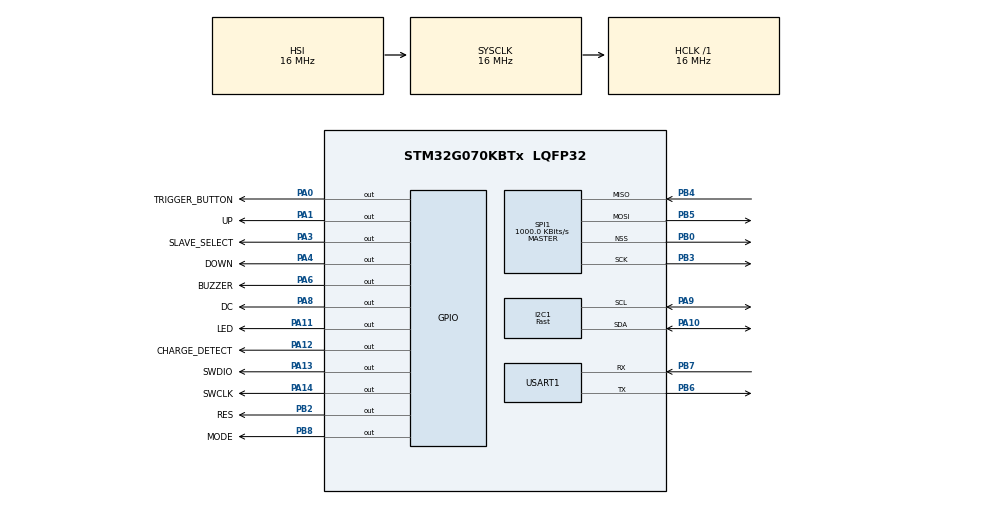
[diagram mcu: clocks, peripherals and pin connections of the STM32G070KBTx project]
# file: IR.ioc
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I2C1.I2C_Speed_Mode=I2C_Fast
I2C1.Timing=0x0010061A
Mcu.Family=STM32G0
Mcu.Name=STM32G070KBTx
Mcu.Package=LQFP32
NRST.GPIO_Label=NRST
NRST.Signal=GPIO_Output
PA0.GPIO_Label=TRIGGER_BUTTON
PA0.Signal=GPIO_Output
PA1.GPIO_Label=UP
PA1.Signal=GPIO_Output
PA10.Mode=I2C
PA10.Signal=I2C1_SDA
PA11\ [PA9].GPIO_Label=LED
PA11\ [PA9].Signal=GPIO_Output
PA12\ [PA10].GPIO_Label=CHARGE_DETECT
PA12\ [PA10].Signal=GPIO_Output
PA13.GPIO_Label=SWDIO
PA13.Signal=GPIO_Output
PA14-BOOT0.GPIO_Label=SWCLK
PA14-BOOT0.Signal=GPIO_Output
PA3.GPIO_Label=SLAVE_SELECT
PA3.PinState=GPIO_PIN_SET
PA3.Signal=GPIO_Output
PA4.GPIO_Label=DOWN
PA4.Signal=GPIO_Output
PA6.GPIO_Label=BUZZER
PA6.Signal=GPIO_Output
PA8.GPIO_Label=DC
PA8.Signal=GPIO_Output
PA9.Mode=I2C
PA9.Signal=I2C1_SCL
PB0.Mode=NSS_Signal_Hard_Output
PB0.Signal=SPI1_NSS
PB2.GPIO_Label=RES
PB2.Signal=GPIO_Output
PB3.Mode=Full_Duplex_Master
PB3.Signal=SPI1_SCK
PB4.Mode=Full_Duplex_Master
PB4.Signal=SPI1_MISO
PB5.Mode=Full_Duplex_Master
PB5.Signal=SPI1_MOSI
PB6.Mode=Asynchronous
PB6.Signal=USART1_TX
PB7.Mode=Asynchronous
PB7.Signal=USART1_RX
PB8.GPIO_Label=MODE
PB8.Signal=GPIO_Output
ProjectManager.HeapSize=0x200
ProjectManager.StackSize=0x400
ProjectManager.TargetToolchain=MDK-ARM V5.27
RCC.AHBFreq_Value=16000000
RCC.CortexFreq_Value=16000000
RCC.EXTERNAL_CLOCK_VALUE=48000
RCC.HCLKFreq_Value=16000000
RCC.HSE_VALUE=8000000
RCC.HSI_VALUE=16000000
RCC.LSE_VALUE=32768
RCC.SYSCLKFreq_VALUE=16000000
RCC.VCOOutputFreq_Value=128000000
SPI1.BaudRatePrescaler=SPI_BAUDRATEPRESCALER_16
SPI1.CalculateBaudRate=1000.0 KBits/s
SPI1.Direction=SPI_DIRECTION_2LINES
SPI1.Mode=SPI_MODE_MASTER
SPI1.VirtualNSS=VM_NSSHARD
SPI1.VirtualType=VM_MASTER
USART1.VirtualMode-Asynchronous=VM_ASYNC
USART1.WordLength=WORDLENGTH_7B
VP_SYS_VS_DBSignals.Mode=DisableDeadBatterySignals
board=custom

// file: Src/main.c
/* USER CODE BEGIN Header */
/**
  ******************************************************************************
  * @file           : main.c
  * @brief          : Main program body
  ******************************************************************************
  * @attention
  *
  * <h2><center>&copy; Copyright (c) 2020 STMicroelectronics.
  * All rights reserved.</center></h2>
  *
  * This software component is licensed by ST under BSD 3-Clause license,
  * the "License"; You may not use this file except in compliance with the
  * License. You may obtain a copy of the License at:
  *                        opensource.org/licenses/BSD-3-Clause
  *
  ******************************************************************************
  */
/* USER CODE END Header */

#include "main.h"

/* USER CODE BEGIN Includes */
//#include "st7735.h"

/* USER CODE END Includes */

I2C_HandleTypeDef hi2c1;

SPI_HandleTypeDef hspi1;

UART_HandleTypeDef huart1;

void SystemClock_Config(void);
static void MX_GPIO_Init(void);
static void MX_I2C1_Init(void);
static void MX_SPI1_Init(void);
static void MX_USART1_UART_Init(void);

int main(void)
{

  /* MCU Configuration--------------------------------------------------------*/

  /* Reset of all peripherals, Initializes the Flash interface and the Systick. */
  HAL_Init();

  /* Configure the system clock */
  SystemClock_Config();

  /* Initialize all configured peripherals */
  MX_GPIO_Init();
  MX_I2C1_Init();
  MX_SPI1_Init();
  MX_USART1_UART_Init();

  /* Infinite loop */
  while (1)
  {

  }
}

void SystemClock_Config(void)
{
  RCC_OscInitTypeDef RCC_OscInitStruct = {0};
  RCC_ClkInitTypeDef RCC_ClkInitStruct = {0};
  RCC_PeriphCLKInitTypeDef PeriphClkInit = {0};

  /** Configure the main internal regulator output voltage
  */
  HAL_PWREx_ControlVoltageScaling(PWR_REGULATOR_VOLTAGE_SCALE1);
  /** Initializes the CPU, AHB and APB busses clocks
  */
  RCC_OscInitStruct.OscillatorType = RCC_OSCILLATORTYPE_HSI;
  RCC_OscInitStruct.HSIState = RCC_HSI_ON;
  RCC_OscInitStruct.HSIDiv = RCC_HSI_DIV1;
  RCC_OscInitStruct.HSICalibrationValue = RCC_HSICALIBRATION_DEFAULT;
  RCC_OscInitStruct.PLL.PLLState = RCC_PLL_NONE;
  if (HAL_RCC_OscConfig(&RCC_OscInitStruct) != HAL_OK)
  {
    Error_Handler();
  }
  /** Initializes the CPU, AHB and APB busses clocks
  */
  RCC_ClkInitStruct.ClockType = RCC_CLOCKTYPE_HCLK|RCC_CLOCKTYPE_SYSCLK
                              |RCC_CLOCKTYPE_PCLK1;
  RCC_ClkInitStruct.SYSCLKSource = RCC_SYSCLKSOURCE_HSI;
  RCC_ClkInitStruct.AHBCLKDivider = RCC_SYSCLK_DIV1;
  RCC_ClkInitStruct.APB1CLKDivider = RCC_HCLK_DIV1;

  if (HAL_RCC_ClockConfig(&RCC_ClkInitStruct, FLASH_LATENCY_0) != HAL_OK)
  {
    Error_Handler();
  }
  /** Initializes the peripherals clocks
  */
  PeriphClkInit.PeriphClockSelection = RCC_PERIPHCLK_USART1|RCC_PERIPHCLK_I2C1;
  PeriphClkInit.Usart1ClockSelection = RCC_USART1CLKSOURCE_PCLK1;
  PeriphClkInit.I2c1ClockSelection = RCC_I2C1CLKSOURCE_PCLK1;
  if (HAL_RCCEx_PeriphCLKConfig(&PeriphClkInit) != HAL_OK)
  {
    Error_Handler();
  }
}

static void MX_I2C1_Init(void)
{

  hi2c1.Instance = I2C1;
  hi2c1.Init.Timing = 0x0010061A;
  hi2c1.Init.OwnAddress1 = 0;
  hi2c1.Init.AddressingMode = I2C_ADDRESSINGMODE_7BIT;
  hi2c1.Init.DualAddressMode = I2C_DUALADDRESS_DISABLE;
  hi2c1.Init.OwnAddress2 = 0;
  hi2c1.Init.OwnAddress2Masks = I2C_OA2_NOMASK;
  hi2c1.Init.GeneralCallMode = I2C_GENERALCALL_DISABLE;
  hi2c1.Init.NoStretchMode = I2C_NOSTRETCH_DISABLE;
  if (HAL_I2C_Init(&hi2c1) != HAL_OK)
  {
    Error_Handler();
  }
  /** Configure Analogue filter
  */
  if (HAL_I2CEx_ConfigAnalogFilter(&hi2c1, I2C_ANALOGFILTER_ENABLE) != HAL_OK)
  {
    Error_Handler();
  }
  /** Configure Digital filter
  */
  if (HAL_I2CEx_ConfigDigitalFilter(&hi2c1, 0) != HAL_OK)
  {
    Error_Handler();
  }

}

static void MX_SPI1_Init(void)
{

  /* SPI1 parameter configuration*/
  hspi1.Instance = SPI1;
  hspi1.Init.Mode = SPI_MODE_MASTER;
  hspi1.Init.Direction = SPI_DIRECTION_2LINES;
  hspi1.Init.DataSize = SPI_DATASIZE_4BIT;
  hspi1.Init.CLKPolarity = SPI_POLARITY_LOW;
  hspi1.Init.CLKPhase = SPI_PHASE_1EDGE;
  hspi1.Init.NSS = SPI_NSS_HARD_OUTPUT;
  hspi1.Init.BaudRatePrescaler = SPI_BAUDRATEPRESCALER_16;
  hspi1.Init.FirstBit = SPI_FIRSTBIT_MSB;
  hspi1.Init.TIMode = SPI_TIMODE_DISABLE;
  hspi1.Init.CRCCalculation = SPI_CRCCALCULATION_DISABLE;
  hspi1.Init.CRCPolynomial = 7;
  hspi1.Init.CRCLength = SPI_CRC_LENGTH_DATASIZE;
  hspi1.Init.NSSPMode = SPI_NSS_PULSE_ENABLE;
  if (HAL_SPI_Init(&hspi1) != HAL_OK)
  {
    Error_Handler();
  }

}

static void MX_USART1_UART_Init(void)
{

  huart1.Instance = USART1;
  huart1.Init.BaudRate = 115200;
  huart1.Init.WordLength = UART_WORDLENGTH_7B;
  huart1.Init.StopBits = UART_STOPBITS_1;
  huart1.Init.Parity = UART_PARITY_NONE;
  huart1.Init.Mode = UART_MODE_TX_RX;
  huart1.Init.HwFlowCtl = UART_HWCONTROL_NONE;
  huart1.Init.OverSampling = UART_OVERSAMPLING_16;
  huart1.Init.OneBitSampling = UART_ONE_BIT_SAMPLE_DISABLE;
  huart1.Init.ClockPrescaler = UART_PRESCALER_DIV1;
  huart1.AdvancedInit.AdvFeatureInit = UART_ADVFEATURE_NO_INIT;
  if (HAL_UART_Init(&huart1) != HAL_OK)
  {
    Error_Handler();
  }
  if (HAL_UARTEx_SetTxFifoThreshold(&huart1, UART_TXFIFO_THRESHOLD_1_8) != HAL_OK)
  {
    Error_Handler();
  }
  if (HAL_UARTEx_SetRxFifoThreshold(&huart1, UART_RXFIFO_THRESHOLD_1_8) != HAL_OK)
  {
    Error_Handler();
  }
  if (HAL_UARTEx_DisableFifoMode(&huart1) != HAL_OK)
  {
    Error_Handler();
  }

}

static void MX_GPIO_Init(void)
{
  GPIO_InitTypeDef GPIO_InitStruct = {0};

  /* GPIO Ports Clock Enable */
  __HAL_RCC_GPIOA_CLK_ENABLE();
  __HAL_RCC_GPIOB_CLK_ENABLE();

  /*Configure GPIO pin Output Level */
  HAL_GPIO_WritePin(GPIOA, TRIGGER_BUTTON_Pin|UP_Pin|DOWN_Pin|BUZZER_Pin
                          |DC_Pin|LED_Pin|CHARGE_DETECT_Pin|SWDIO_Pin
                          |SWCLK_Pin, GPIO_PIN_RESET);

  /*Configure GPIO pin Output Level */
  HAL_GPIO_WritePin(SLAVE_SELECT_GPIO_Port, SLAVE_SELECT_Pin, GPIO_PIN_SET);

  /*Configure GPIO pin Output Level */
  HAL_GPIO_WritePin(GPIOB, RES_Pin|MODE_Pin, GPIO_PIN_RESET);

  /*Configure GPIO pins : TRIGGER_BUTTON_Pin UP_Pin SLAVE_SELECT_Pin DOWN_Pin
                           BUZZER_Pin DC_Pin LED_Pin CHARGE_DETECT_Pin
                           SWDIO_Pin SWCLK_Pin */
  GPIO_InitStruct.Pin = TRIGGER_BUTTON_Pin|UP_Pin|SLAVE_SELECT_Pin|DOWN_Pin
                          |BUZZER_Pin|DC_Pin|LED_Pin|CHARGE_DETECT_Pin
                          |SWDIO_Pin|SWCLK_Pin;
  GPIO_InitStruct.Mode = GPIO_MODE_OUTPUT_PP;
  GPIO_InitStruct.Pull = GPIO_NOPULL;
  GPIO_InitStruct.Speed = GPIO_SPEED_FREQ_LOW;
  HAL_GPIO_Init(GPIOA, &GPIO_InitStruct);

  /*Configure GPIO pins : RES_Pin MODE_Pin */
  GPIO_InitStruct.Pin = RES_Pin|MODE_Pin;
  GPIO_InitStruct.Mode = GPIO_MODE_OUTPUT_PP;
  GPIO_InitStruct.Pull = GPIO_NOPULL;
  GPIO_InitStruct.Speed = GPIO_SPEED_FREQ_LOW;
  HAL_GPIO_Init(GPIOB, &GPIO_InitStruct);

}

void Error_Handler(void)
{
}

/************************ (C) COPYRIGHT STMicroelectronics *****END OF FILE****/
